# CM41x_M4 register map
Vendor: Analog Devices; Series: CM41x_M4; File version: 1p0
CPU: CM4 r0p1, little endian, MPU, FPU, 4 interrupt priority bits
Registers are 32-bit, read-write, reset 0x0 unless marked. A register's access mark holds for its fields unless they carry their own. Offsets are from the block's base; [hi:lo] are bit positions; {n}, {i} and the like mark numbered series.

## SCS0
Base 0xE000E000
0x04 ICTR — Interrupt Control Type Register
  [4:0] INTLINESNUM ro — Total number of interrupt lines in groups of 32
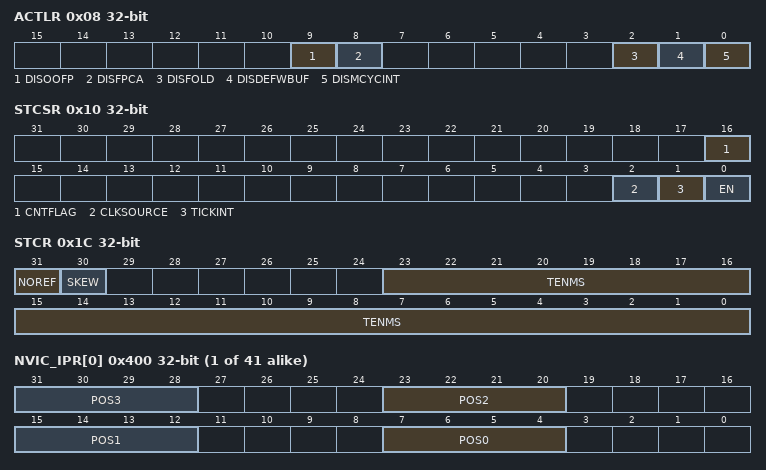
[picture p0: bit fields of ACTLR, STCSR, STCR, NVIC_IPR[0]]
0x08 ACTLR — Auxiliary Control Register
  [9] DISOOFP range 0x00000000..0x00000001 — Disables floating point instructions completing out of order with respect to integer instructions.
  [8] DISFPCA range 0x00000000..0x00000001 — Disable automatic update of CONTROL.FPCA. See Exceptions on page 7-8 for more information.
  [2] DISFOLD range 0x00000000..0x00000001 — Disables IT folding
  [1] DISDEFWBUF range 0x00000000..0x00000001 — Disables write buffer us during default memorty map accesses
  [0] DISMCYCINT range 0x00000000..0x00000001 — Disables interruption of multi-cycle instructions
0x10 STCSR — SysTick Control and Status Register
  [16] CNTFLAG ro — Returns 1 if timer counted to 0 since last time this was read
  [2] CLKSOURCE ro — Clock source
  [1] TICKINT range 0x00000000..0x00000001
  [0] EN range 0x00000000..0x00000001 — Enable SysTick counter
0x14 STRVR — SysTick Reload Value Register
  [23:0] RELOAD range 0x00000000..0x00FFFFFF — Value to load into the SysTick Current Value Register when the counter reaches 0
0x18 STCVR — SysTick Current Value Register
  [23:0] CUR range 0x00000000..0x00FFFFFF — Current value at the time the register is accessed
0x1C STCR — SysTick Calibration Value Register
  [31] NOREF ro — Reads as one
  [30] SKEW ro — Reads as one
  [23:0] TENMS ro — Reads as zero
{0x100+4i} NVIC_ISER[{i}] (i=0..5) — Irq Set Enable Register n
  [31:0] SETENA range 0x00000000..0xFFFFFFFF — Writing 0 to a SETENA bit has no effect, writing 1 to a bit enables the corresponding interrupt
{0x180+4i} NVIC_ICER[{i}] (i=0..5) — Irq Clear Enable Register n
  [31:0] CLRENA range 0x00000000..0xFFFFFFFF — Writing 0 to a CLRENA bit has no effect, writing 1 to a bit disables the corresponding interrupt
{0x200+4i} NVIC_ISPR[{i}] (i=0..5) — Irq Set Pending Register n
  [31:0] SETPEND range 0x00000000..0xFFFFFFFF — Writing 0 to a SETPEND bit has no effect, writing 1 to a bit pends the corresponding interrupt
{0x280+4i} NVIC_ICPR[{i}] (i=0..5) — Irq Clear Pending Register n
  [31:0] CLRPEND range 0x00000000..0xFFFFFFFF — Writing 0 to a CLRPEND bit has no effect, writing 1 to a bit clears the corresponding pending interrupt
{0x300+4i} NVIC_IABR[{i}] (i=0..5) — Irq Active Bit Register n
  [31:0] ACTIVE ro — Interrupt active flags
{0x400+4i} NVIC_IPR[{i}] (i=0..40) — Irq Priority Register nn
  [8n+7:8n+4] POS{n} range 0x00000000..0x0000000F (n=0..3) — Priority of interrupt in Position {n}
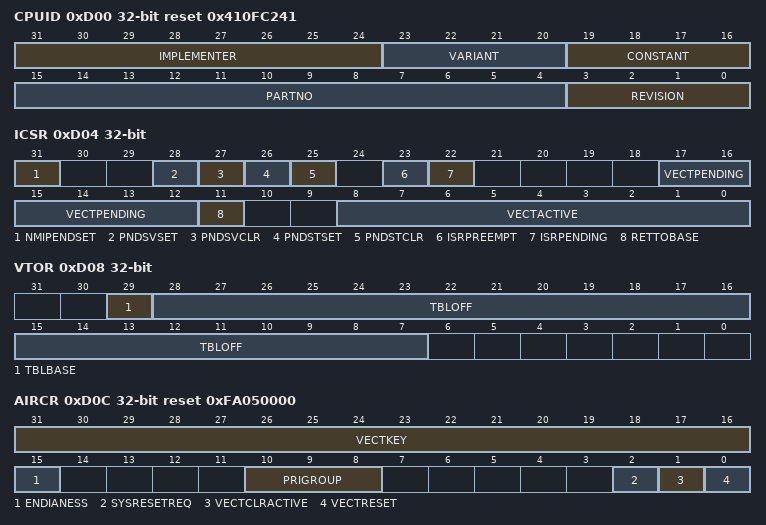
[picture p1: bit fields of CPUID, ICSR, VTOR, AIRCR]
0xD00 CPUID reset 0x410FC241 — CPUID Base Register
  [31:24] IMPLEMENTER ro — Implementor code
  [23:20] VARIANT ro — Implementation defined variant number
  [19:16] CONSTANT ro — Reads as 0xC
  [15:4] PARTNO ro — Number of processor within family
  [3:0] REVISION ro — Implementation defined revision number
0xD04 ICSR — Interrupt Control State Register
  [31] NMIPENDSET range 0x00000000..0x00000001 — Set pending NMI bit
  [28] PNDSVSET range 0x00000000..0x00000001 — Set pending pendSV bit
  [27] PNDSVCLR range 0x00000000..0x00000001 — Clear pending pendSV bit
  [26] PNDSTSET range 0x00000000..0x00000001 — Set a pending SysTick bit
  [25] PNDSTCLR range 0x00000000..0x00000001 — Clear pending SysTick bit
  [23] ISRPREEMPT ro — You must only use this at debug time
  [22] ISRPENDING ro — Interrupt pending flag
  [17:12] VECTPENDING ro — Pending ISR number field
  [11] RETTOBASE ro — This bit is 1 when the set of all active exceptions minus the IPSR_current_exception yields the empty set
  [8:0] VECTACTIVE ro — Active ISR number field
0xD08 VTOR — Vector Table Offset Register
  [29] TBLBASE range 0x00000000..0x00000001 — Table base is in Code (0) or RAM (1)
  [28:7] TBLOFF range 0x00000000..0x003FFFFF — Vector table base offset field
0xD0C AIRCR reset 0xFA050000 — Application Interrupt/Reset Control Register
  [31:16] VECTKEY range 0x00000000..0x0000FFFF — Register key
  [15] ENDIANESS ro — Data endianness bit
  [10:8] PRIGROUP range 0x00000000..0x00000007 — Interrupt priority grouping field
  [2] SYSRESETREQ range 0x00000000..0x00000001 — Causes a signal to be asserted to the outer system that indicates a reset is requested
  [1] VECTCLRACTIVE range 0x00000000..0x00000001 — Clears all active state information for active NMI, fault, and interrupts
  [0] VECTRESET range 0x00000000..0x00000001 — System Reset bit
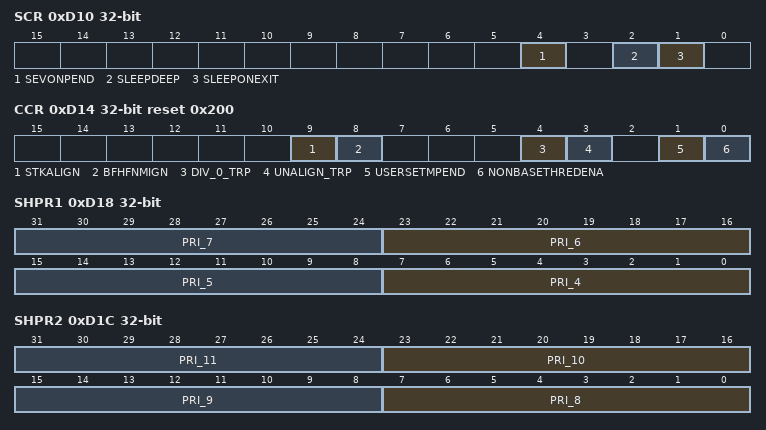
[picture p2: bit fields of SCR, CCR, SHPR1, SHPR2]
0xD10 SCR — System Control Register
  [4] SEVONPEND range 0x00000000..0x00000001 — When enabled, this causes WFE to wake up when an interrupt moves from inactive to pended
  [2] SLEEPDEEP range 0x00000000..0x00000001 — Sleep deep bit
  [1] SLEEPONEXIT range 0x00000000..0x00000001 — Sleep on exit when returning from Handler mode to Thread mode
0xD14 CCR reset 0x200 — Configuration Control Register
  [9] STKALIGN range 0x00000000..0x00000001 — Stack alignment bit
  [8] BFHFNMIGN range 0x00000000..0x00000001 — When enabled, this causes handlers running at priority -1 and -2 (Hard Fault, NMI, and FAULTMASK escalated handlers) to ignore Data Bus faults caused by load and store instructions
  [4] DIV_0_TRP range 0x00000000..0x00000001 — Trap on Divide by 0
  [3] UNALIGN_TRP range 0x00000000..0x00000001 — Trap for unaligned access
  [1] USERSETMPEND range 0x00000000..0x00000001 — If written as 1, enables user code to write the Software Trigger Interrupt register to trigger (pend) a Main exception, which is one associated with the Main stack pointer
  [0] NONBASETHREDENA range 0x00000000..0x00000001 — When 0, default, It is only possible to enter Thread mode when returning from the last exception
0xD18 SHPR1 — System Handlers 4-7 Priority Register
  [8n-25:8n-32] PRI_{n} range 0x00000000..0x000000FF (n=4..7) — Priority of system handler {n}
0xD1C SHPR2 — System Handlers 8-11 Priority Register
  [8n-57:8n-64] PRI_{n} range 0x00000000..0x000000FF (n=8..11) — Priority of system handler {n}
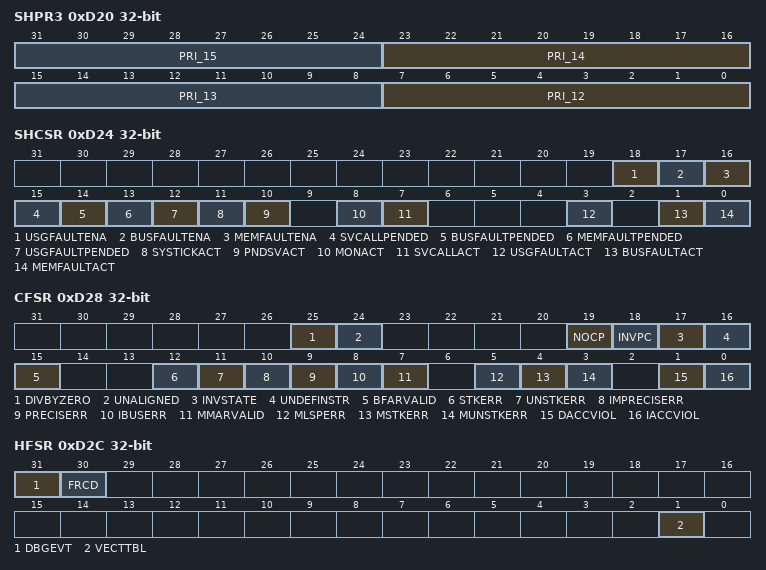
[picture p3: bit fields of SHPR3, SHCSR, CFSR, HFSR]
0xD20 SHPR3 — System Handlers 12-15 Priority Register
  [8n-89:8n-96] PRI_{n} range 0x00000000..0x000000FF (n=12..15) — Priority of system handler {n}
0xD24 SHCSR — System Handler Control and State Register
  [18] USGFAULTENA range 0x00000000..0x00000001 — Usage fault system handler enable
  [17] BUSFAULTENA range 0x00000000..0x00000001 — Bus fault system handler enable
  [16] MEMFAULTENA range 0x00000000..0x00000001 — MemManage fault system handler enable
  [15] SVCALLPENDED ro — SVCall pended flag
  [14] BUSFAULTPENDED ro — BusFault pended flag
  [13] MEMFAULTPENDED ro — MemManage pended flag
  [12] USGFAULTPENDED ro — usage fault pended flag
  [11] SYSTICKACT ro — SysTick active flag
  [10] PNDSVACT ro — PendSV active flag
  [8] MONACT ro — the Monitor active flag
  [7] SVCALLACT ro — SVCall active flag
  [3] USGFAULTACT ro — UsageFault active flag
  [1] BUSFAULTACT ro — BusFault active flag
  [0] MEMFAULTACT ro — MemManage active flag
0xD28 CFSR — Configurable Fault Status Registers
  [25] DIVBYZERO range 0x00000000..0x00000001 — When DIV_0_TRP (see Configuration Control Register on page 8-26) is enabled and an SDIV or UDIV instruction is used with a divisor of 0, this fault occurs The instruction is executed and the return PC points to it
  [24] UNALIGNED range 0x00000000..0x00000001 — When UNALIGN_TRP is enabled (see Configuration Control Register on page 8-26), and there is an attempt to make an unaligned memory access, then this fault occurs
  [19] NOCP range 0x00000000..0x00000001 — Attempt to use a coprocessor instruction
  [18] INVPC range 0x00000000..0x00000001 — Attempt to load EXC_RETURN into PC illegally
  [17] INVSTATE range 0x00000000..0x00000001 — Invalid combination of EPSR and instruction, for reasons other than UNDEFINED instruction
  [16] UNDEFINSTR range 0x00000000..0x00000001 — The UNDEFINSTR flag is set when the processor attempts to execute an undefined instruction
  [15] BFARVALID range 0x00000000..0x00000001 — This bit is set if the Bus Fault Address Register (BFAR) contains a valid address
  [12] STKERR range 0x00000000..0x00000001 — Stacking from exception has caused one or more bus faults
  [11] UNSTKERR range 0x00000000..0x00000001 — Unstack from exception return has caused one or more bus faults
  [10] IMPRECISERR range 0x00000000..0x00000001 — Imprecise data bus error
  [9] PRECISERR range 0x00000000..0x00000001 — Precise data bus error return
  [8] IBUSERR range 0x00000000..0x00000001 — Instruction bus error flag
  [7] MMARVALID range 0x00000000..0x00000001 — Memory Manage Address Register (MMAR) address valid flag
  [5] MLSPERR — When derived MemManage fault has occurred.
    0=EN000 (Unknown); 1=EN001 (Unknown)
  [4] MSTKERR range 0x00000000..0x00000001 — Stacking from exception has caused one or more access violations
  [3] MUNSTKERR range 0x00000000..0x00000001 — Unstack from exception return has caused one or more access violations
  [1] DACCVIOL range 0x00000000..0x00000001 — Data access violation flag
  [0] IACCVIOL range 0x00000000..0x00000001 — Instruction access violation flag
0xD2C HFSR — Hard Fault Status Register
  [31] DBGEVT range 0x00000000..0x00000001 — This bit is set if there is a fault related to debug
  [30] FRCD range 0x00000000..0x00000001 — Hard Fault activated because a Configurable Fault was received and cannot activate because of priority or because the Configurable Fault is disabled
  [1] VECTTBL range 0x00000000..0x00000001 — This bit is set if there is a fault because of vector table read on exception processing (Bus Fault)
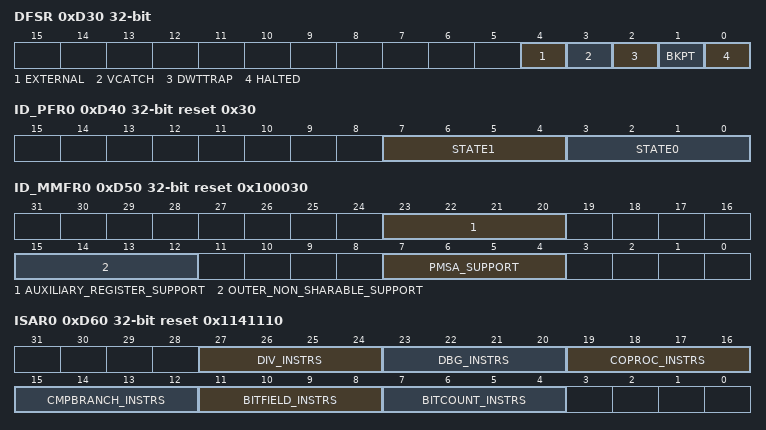
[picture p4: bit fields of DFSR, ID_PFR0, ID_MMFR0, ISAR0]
0xD30 DFSR — Debug Fault Status Register
  [4] EXTERNAL range 0x00000000..0x00000001 — External debug request flag
  [3] VCATCH range 0x00000000..0x00000001 — Vector catch flag
  [2] DWTTRAP range 0x00000000..0x00000001 — Data Watchpoint and Trace (DWT) flag
  [1] BKPT range 0x00000000..0x00000001 — BKPT flag
  [0] HALTED range 0x00000000..0x00000001 — Halt request flag
0xD34 MMFAR — Mem Manage Fault Address Register
  [31:0] ADDR range 0x00000000..0xFFFFFFFF — Mem Manage fault address field
0xD38 BFAR — Bus Fault Address Register
  [31:0] ADDR range 0x00000000..0xFFFFFFFF — Bus fault address field
0xD3C AFSR — Auxiliary Fault Status Register
  [31:0] IMPDEF range 0x00000000..0xFFFFFFFF — Implementation defined
0xD40 ID_PFR0 reset 0x30 — Processor Feature register0
  [7:4] STATE1 ro — State1 (T-bit == 1)
  [3:0] STATE0 ro — State0 (T-bit == 0)
0xD44 ID_PFR1 reset 0x200 — Processor Feature register1
  [11:8] MICROCONTROLLER_PROGRAMMERS_MODEL ro
0xD48 ID_DFR0 reset 0x100000 — Debug Feature register0
  [23:20] MICROCONTROLLER_DBG_MODEL ro — Microcontroller Debug Model - memory mapped
0xD4C ID_AFR0 — Auxiliary Feature register0
  [31:0] ID_AFR0 ro
0xD50 ID_MMFR0 reset 0x100030 — Memory Model Feature register0
  [23:20] AUXILIARY_REGISTER_SUPPORT ro, [15:12] OUTER_NON_SHARABLE_SUPPORT ro, [7:4] PMSA_SUPPORT ro
0xD54 ID_MMFR1 — Memory Model Feature register1
  [31:0] ID_MMFR1 ro
0xD58 ID_MMFR2 — Memory Model Feature register2
  [27:24] WAIT_FOR_INTERRUPT_STALLING ro
0xD5C ID_MMFR3 — Memory Model Feature register3
  [31:0] ID_MMFR3 ro
0xD60 ISAR0 reset 0x1141110 — ISA Feature register0
  [27:24] DIV_INSTRS ro — Divide instructions
  [23:20] DBG_INSTRS ro — Debug instructions
  [19:16] COPROC_INSTRS ro — Coprocessor instructions
  [15:12] CMPBRANCH_INSTRS ro — CmpBranch instructions
  [11:8] BITFIELD_INSTRS ro — BitField instructions
  [7:4] BITCOUNT_INSTRS ro — BitCount instructions
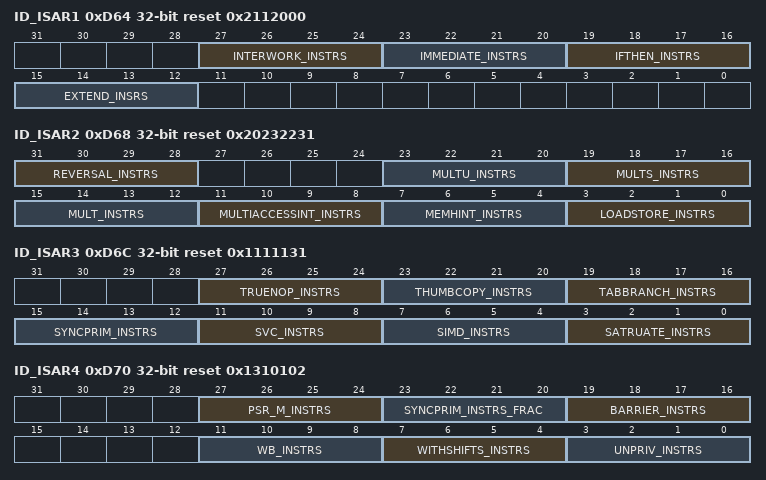
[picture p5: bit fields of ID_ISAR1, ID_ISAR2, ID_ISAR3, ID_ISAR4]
0xD64 ID_ISAR1 reset 0x2112000 — ISA Feature register1
  [27:24] INTERWORK_INSTRS ro — Interwork instructions
  [23:20] IMMEDIATE_INSTRS ro — Immediate instructions
  [19:16] IFTHEN_INSTRS ro — IfThen instructions
  [15:12] EXTEND_INSRS ro — Extend instructions
0xD68 ID_ISAR2 reset 0x20232231 — ISA Feature register2
  [31:28] REVERSAL_INSTRS ro — Reversal instructions
  [23:20] MULTU_INSTRS ro — Multiply instructions (advanced, unsigned)
  [19:16] MULTS_INSTRS ro — Multiply instructions (advanced, signed)
  [15:12] MULT_INSTRS ro — Multiply instructions
  [11:8] MULTIACCESSINT_INSTRS ro — Multi-Access interruptible instructions
  [7:4] MEMHINT_INSTRS ro — MemoryHint instructions
  [3:0] LOADSTORE_INSTRS ro — LoadStore instructions
0xD6C ID_ISAR3 reset 0x1111131 — ISA Feature register3
  [27:24] TRUENOP_INSTRS ro — TrueNOP instructions
  [23:20] THUMBCOPY_INSTRS ro — ThumbCopy instructions
  [19:16] TABBRANCH_INSTRS ro — TableBranch instructions
  [15:12] SYNCPRIM_INSTRS ro — SyncPrim instructions
  [11:8] SVC_INSTRS ro — SVC instructions
  [7:4] SIMD_INSTRS ro — SIMD instructions
  [3:0] SATRUATE_INSTRS ro — Saturate instructions
0xD70 ID_ISAR4 reset 0x1310102 — ISA Feature register4
  [27:24] PSR_M_INSTRS ro
  [23:20] SYNCPRIM_INSTRS_FRAC ro
  [19:16] BARRIER_INSTRS ro — Barrier instructions
  [11:8] WB_INSTRS ro — Writeback instructions
  [7:4] WITHSHIFTS_INSTRS ro — WithShift instructions
  [3:0] UNPRIV_INSTRS ro — Unprivileged instructions
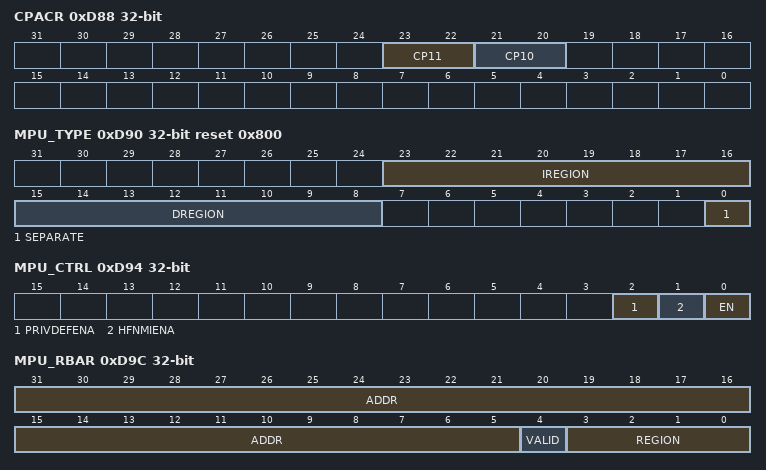
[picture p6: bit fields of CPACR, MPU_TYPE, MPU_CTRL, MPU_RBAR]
0xD88 CPACR — Coprocessor Access Control Register
  [23:22] CP11 range 0x00000000..0x00000003 — Access privileges for coprocessor 11
  [21:20] CP10 range 0x00000000..0x00000003 — Access privileges for coprocessor 10
0xD90 MPU_TYPE reset 0x800
  [23:16] IREGION ro — Because the processor core uses only a unified MPU, IREGION always contains 0x00
  [15:8] DREGION ro — Number of supported MPU regions field
  [0] SEPARATE ro — Because the processor core uses only a unified MPU, SEPARATE is always 0
0xD94 MPU_CTRL — MPU Control Register
  [2] PRIVDEFENA range 0x00000000..0x00000001 — This bit enables the default memory map for privileged access, as a background region, when the MPU is enabled
  [1] HFNMIENA range 0x00000000..0x00000001 — This bit enables the MPU when in Hard Fault, NMI, and FAULTMASK escalated handlers
  [0] EN range 0x00000000..0x00000001 — MPU enable bit
0xD98 MPU_RNR — MPU Region Number Register
  [7:0] REGION range 0x00000000..0x000000FF — Region select field
0xD9C MPU_RBAR — MPU Region Base Address Register
  [31:5] ADDR range 0x00000000..0x07FFFFFF — Region base address field
  [4] VALID range 0x00000000..0x00000001 — MPU Region Number valid bit
  [3:0] REGION range 0x00000000..0x0000000F — MPU region override field
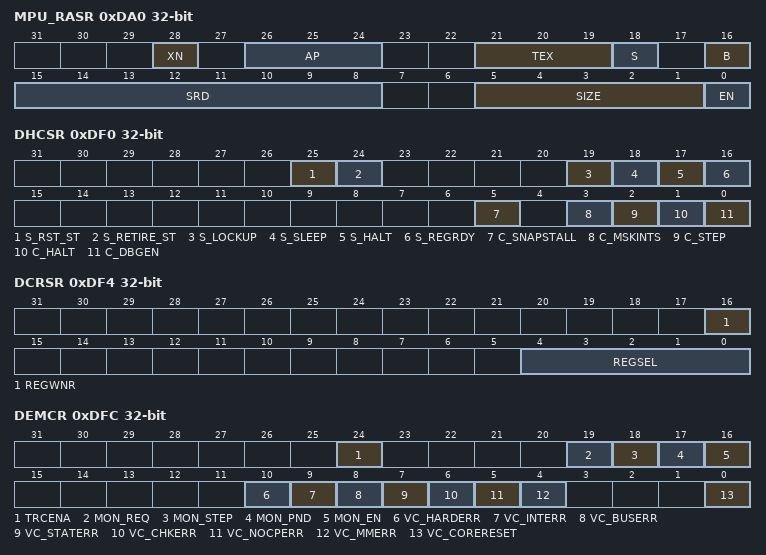
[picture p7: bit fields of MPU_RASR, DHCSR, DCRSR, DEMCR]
0xDA0 MPU_RASR — MPU Region Attribute and Size Register
  [28] XN range 0x00000000..0x00000001 — Instruction access disable bit
  [26:24] AP range 0x00000000..0x00000007 — Data access permission field
  [21:19] TEX range 0x00000000..0x00000007 — Type extension field
  [18] S range 0x00000000..0x00000001 — Shareable bit
  [16] B range 0x00000000..0x00000001 — Bufferable bit
  [15:8] SRD range 0x00000000..0x000000FF — Sub-Region Disable (SRD) field
  [5:1] SIZE range 0x00000000..0x0000001F — MPU Protection Region Size Field
  [0] EN range 0x00000000..0x00000001 — Region enable bit
{0xD9C+8i} MPU_RBAR_A{i} (i=1..3) — MPU Alias {i} Region Base Address register
  [31:0] MPU_RBAR_A{i} range 0x00000000..0xFFFFFFFF
{0xDA0+8i} MPU_RASR_A{i} (i=1..3) — MPU Alias {i} Region Attribute and Size register
  [31:0] MPU_RASR_A{i} range 0x00000000..0xFFFFFFFF
0xDF0 DHCSR — Debug Halting Control and Status Register
  [25] S_RST_ST ro — Indicates that the core has been reset, or is now being reset, since the last time this bit was read
  [24] S_RETIRE_ST ro — Indicates that an instruction has completed since last read
  [19] S_LOCKUP ro — Reads as one if the core is running (not halted) and a lockup condition is present
  [18] S_SLEEP ro — Indicates that the core is sleeping (WFI, WFE, or SLEEP-ON-EXIT)
  [17] S_HALT ro — The core is in debug state when S_HALT is set
  [16] S_REGRDY ro — Register Read/Write on the Debug Core Register Selector register is available
  [5] C_SNAPSTALL range 0x00000000..0x00000001 — If the core is stalled on a load/store operation the stall ceases and the instruction is forced to complete
  [3] C_MSKINTS range 0x00000000..0x00000001 — Mask interrupts when stepping or running in halted debug
  [2] C_STEP range 0x00000000..0x00000001 — Steps the core in halted debug
  [1] C_HALT range 0x00000000..0x00000001 — Halts the core
  [0] C_DBGEN range 0x00000000..0x00000001 — Enables debug
0xDF4 DCRSR — Deubg Core Register Selector Register
  [16] REGWNR range 0x00000000..0x00000001 — Write = 1, Read = 0
  [4:0] REGSEL range 0x00000000..0x0000001F — Register select
0xDF8 DCRDR — Debug Core Register Data Register
  [31:0] DCRDR range 0x00000000..0xFFFFFFFF
0xDFC DEMCR — Debug Exception and Monitor Control Register
  [24] TRCENA range 0x00000000..0x00000001 — This bit must be set to 1 to enable use of the trace and debug blocks: Data Watchpoint and Trace (DWT), Instrumentation Trace Macrocell (ITM), Embedded Trace Macrocell (ETM), Trace Port Interface Unit (TPIU)
  [19] MON_REQ range 0x00000000..0x00000001 — This enables the monitor to identify how it wakes up
  [18] MON_STEP range 0x00000000..0x00000001 — When MON_EN = 1, this steps the core
  [17] MON_PND range 0x00000000..0x00000001 — Pend the monitor to activate when priority permits
  [16] MON_EN range 0x00000000..0x00000001 — Enable the debug monitor
  [10] VC_HARDERR range 0x00000000..0x00000001 — Debug trap on Hard Fault
  [9] VC_INTERR range 0x00000000..0x00000001 — Debug Trap on interrupt/exception service errors
  [8] VC_BUSERR range 0x00000000..0x00000001 — Debug Trap on normal Bus error
  [7] VC_STATERR range 0x00000000..0x00000001 — Debug trap on Usage Fault state errors
  [6] VC_CHKERR range 0x00000000..0x00000001 — Debug trap on Usage Fault enabled checking errors
  [5] VC_NOCPERR range 0x00000000..0x00000001 — Debug trap on Usage Fault access to Coprocessor that is not present or marked as not present in CAR register
  [4] VC_MMERR range 0x00000000..0x00000001 — Debug trap on Memory Management faults
  [0] VC_CORERESET range 0x00000000..0x00000001 — Reset Vector Catch
0xF00 STIR — Software Trigger Interrupt Register
  [8:0] INTID range 0x00000000..0x000001FF — Interrupt ID field
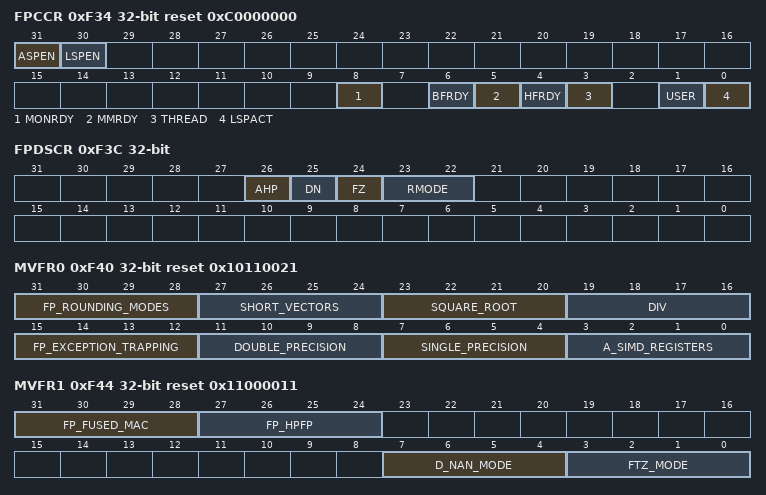
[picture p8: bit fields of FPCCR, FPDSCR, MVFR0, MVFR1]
0xF34 FPCCR reset 0xC0000000 — Floating Point Context Control Register
  [31] ASPEN range 0x00000000..0x00000001 — Automatic State Preservation ENable
  [30] LSPEN range 0x00000000..0x00000001 — Lazy State Preservation ENable
  [8] MONRDY range 0x00000000..0x00000001 — Indicates whether the the software executing when the processor allocated the FP stack frame was able to set the DebugMonitor exception to pending
  [6] BFRDY range 0x00000000..0x00000001 — Indicates whether the software executing when the processor allocated the FP stack frame was able to set the BusFault exception to pending
  [5] MMRDY range 0x00000000..0x00000001 — Indicates whether the software executing when the processor allocated the FP stack frame was able to set the MemManage exception to pending
  [4] HFRDY range 0x00000000..0x00000001 — Indicates whether the software executing when the processor allocated the FP stack frame was able to set the HardFault exception to pending
  [3] THREAD range 0x00000000..0x00000001 — Indicates the processor mode was Thread when it allocated the FP stack frame
  [1] USER range 0x00000000..0x00000001 — Indicates the privilege level of the software executing was User (Unpriviledged) when the processor allocated the FP stack frame
  [0] LSPACT range 0x00000000..0x00000001 — Indicates whether Lazy preservation of the FP state is active
0xF38 FPCAR — Floating-Point Context Address Register
  [30:2] ADDR range 0x00000000..0x1FFFFFFF — Holds the (double-word-aligned) location of the unpopulated floating-point register space allocated on an exception stack frame
0xF3C FPDSCR — Floating Point Default Status Control Register
  [26] AHP range 0x00000000..0x00000001 — Default value for Alternative Half Precision bit
  [25] DN range 0x00000000..0x00000001 — Default value for Default NaN mode bit
  [24] FZ range 0x00000000..0x00000001 — Default value for Flush-to-Zero mode bit
  [23:22] RMODE range 0x00000000..0x00000003 — Default value for Rounding Mode control field
0xF40 MVFR0 reset 0x10110021 — Media and FP Feature Register 0 (MVFR0)
  [31:28] FP_ROUNDING_MODES ro — Indicates the rounding modes supported by the FP floating-point hardware
  [27:24] SHORT_VECTORS ro — Indicates the hardware support for FP short vectors
  [23:20] SQUARE_ROOT ro — Indicates the hardware support for FP square root operations
  [19:16] DIV ro — Indicates the hardware support for FP divide operations
  [15:12] FP_EXCEPTION_TRAPPING ro — Indicates whether the FP hardware implementation supports exception trapping
  [11:8] DOUBLE_PRECISION ro — Indicates the hardware support for FP double-precision operations
  [7:4] SINGLE_PRECISION ro — Indicates the hardware support for FP single-precision operations
  [3:0] A_SIMD_REGISTERS ro — Indicates the size of the FP register bank
0xF44 MVFR1 reset 0x11000011 — Media and FP Feature Register 1 (MVFR1)
  [31:28] FP_FUSED_MAC ro — Indicates whether the FP supports fused multiply accumulate operations
  [27:24] FP_HPFP ro — Indicates whether the FP supports half-precision floating-point conversion operations
  [7:4] D_NAN_MODE ro — Indicates whether the FP hardware implementation supports only the Default NaN mode
  [3:0] FTZ_MODE ro — Indicates whether the FP hardware implementation supports only the Flush-to-Zero mode of operation
{0xFC0+4i} PID{i} (i=4..7) — Peripheral identification register (PID{i})
  [31:0] PID{i} ro
{0xFE0+4i} PID{i} (i=0..3) — Peripheral identification register Bits {8i+7}:{8i} (PID{i})
  [31:0] PID{i} ro
{0xFF0+4i} CID{i} (i=0..3) — Component identification register Bits {8i+7}:{8i} (CID{i})
  [31:0] CID{i} ro
